VERSION ""

NS_ :

BS_:

BU_:

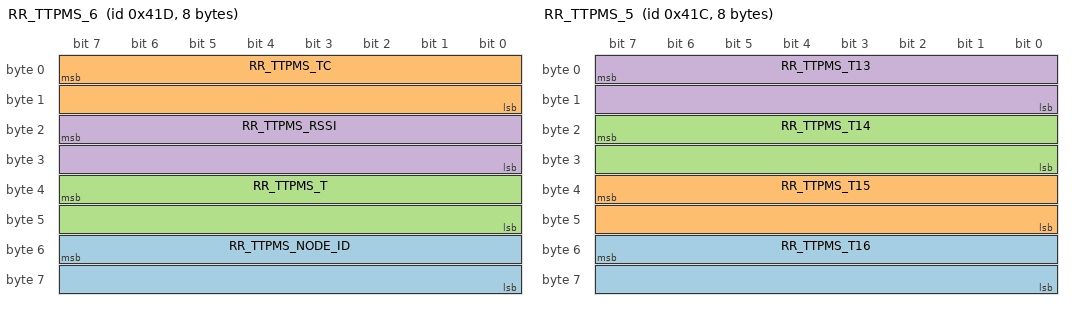
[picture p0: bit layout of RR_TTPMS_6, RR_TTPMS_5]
BO_ 1053 RR_TTPMS_6: 8 Vector__XXX
 SG_ RR_TTPMS_NODE_ID : 55|16@0+ (1,0) [0|65535] "" Vector__XXX
 SG_ RR_TTPMS_TC : 7|16@0+ (1,0) [0|65535] "" Vector__XXX
 SG_ RR_TTPMS_T : 39|16@0+ (0.1,-100) [-100|6453.5] "�C" Vector__XXX
 SG_ RR_TTPMS_RSSI : 23|16@0- (1,0) [-32768|32767] "dBm" Vector__XXX

BO_ 1052 RR_TTPMS_5: 8 Vector__XXX
 SG_ RR_TTPMS_T16 : 55|16@0+ (0.1,-100) [-100|6453.5] "�C" Vector__XXX
 SG_ RR_TTPMS_T15 : 39|16@0+ (0.1,-100) [-100|6453.5] "�C" Vector__XXX
 SG_ RR_TTPMS_T14 : 23|16@0+ (0.1,-100) [-100|6453.5] "�C" Vector__XXX
 SG_ RR_TTPMS_T13 : 7|16@0+ (0.1,-100) [-100|6453.5] "�C" Vector__XXX

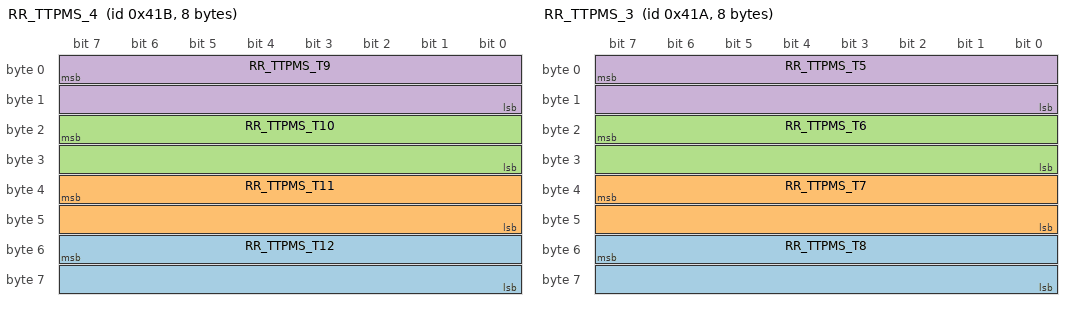
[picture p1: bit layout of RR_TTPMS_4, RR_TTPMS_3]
BO_ 1051 RR_TTPMS_4: 8 Vector__XXX
 SG_ RR_TTPMS_T12 : 55|16@0+ (0.1,-100) [-100|6453.5] "�C" Vector__XXX
 SG_ RR_TTPMS_T11 : 39|16@0+ (0.1,-100) [-100|6453.5] "�C" Vector__XXX
 SG_ RR_TTPMS_T10 : 23|16@0+ (0.1,-100) [-100|6453.5] "�C" Vector__XXX
 SG_ RR_TTPMS_T9 : 7|16@0+ (0.1,-100) [-100|6453.5] "�C" Vector__XXX

BO_ 1050 RR_TTPMS_3: 8 Vector__XXX
 SG_ RR_TTPMS_T8 : 55|16@0+ (0.1,-100) [-100|6453.5] "�C" Vector__XXX
 SG_ RR_TTPMS_T7 : 39|16@0+ (0.1,-100) [-100|6453.5] "�C" Vector__XXX
 SG_ RR_TTPMS_T6 : 23|16@0+ (0.1,-100) [-100|6453.5] "�C" Vector__XXX
 SG_ RR_TTPMS_T5 : 7|16@0+ (0.1,-100) [-100|6453.5] "�C" Vector__XXX

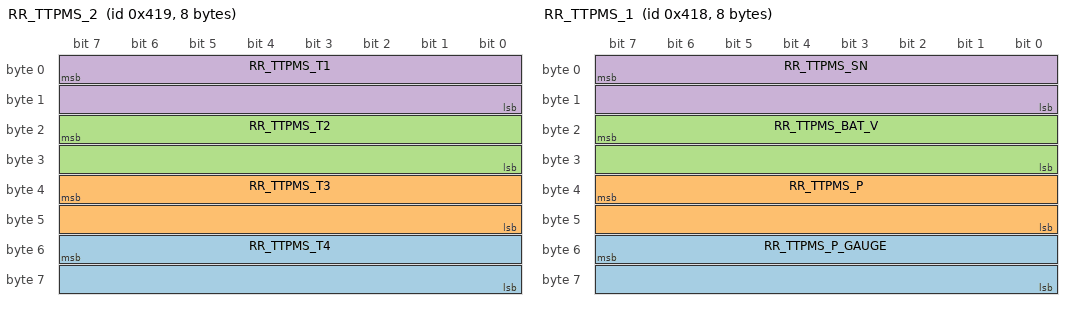
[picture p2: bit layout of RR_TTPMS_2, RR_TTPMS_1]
BO_ 1049 RR_TTPMS_2: 8 Vector__XXX
 SG_ RR_TTPMS_T4 : 55|16@0+ (0.1,-100) [-100|6453.5] "�C" Vector__XXX
 SG_ RR_TTPMS_T3 : 39|16@0+ (0.1,-100) [-100|6453.5] "�C" Vector__XXX
 SG_ RR_TTPMS_T2 : 23|16@0+ (0.1,-100) [-100|6453.5] "�C" Vector__XXX
 SG_ RR_TTPMS_T1 : 7|16@0+ (0.1,-100) [-100|6453.5] "�C" Vector__XXX

BO_ 1048 RR_TTPMS_1: 8 Vector__XXX
 SG_ RR_TTPMS_P_GAUGE : 55|16@0+ (1,0) [0|65535] "mbar" Vector__XXX
 SG_ RR_TTPMS_P : 39|16@0+ (1,0) [0|65535] "mbar" Vector__XXX
 SG_ RR_TTPMS_BAT_V : 23|16@0+ (1,0) [0|65535] "mV" Vector__XXX
 SG_ RR_TTPMS_SN : 7|16@0+ (1,0) [0|65535] "" Vector__XXX

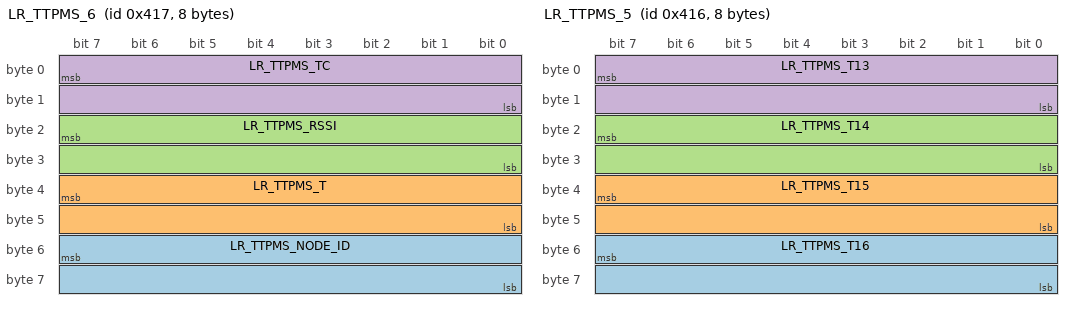
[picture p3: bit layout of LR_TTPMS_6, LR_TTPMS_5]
BO_ 1047 LR_TTPMS_6: 8 Vector__XXX
 SG_ LR_TTPMS_NODE_ID : 55|16@0+ (1,0) [0|65535] "" Vector__XXX
 SG_ LR_TTPMS_T : 39|16@0+ (0.1,-100) [-100|6453.5] "�C" Vector__XXX
 SG_ LR_TTPMS_RSSI : 23|16@0- (1,0) [-32768|32767] "dBm" Vector__XXX
 SG_ LR_TTPMS_TC : 7|16@0+ (1,0) [0|65535] "" Vector__XXX

BO_ 1046 LR_TTPMS_5: 8 Vector__XXX
 SG_ LR_TTPMS_T16 : 55|16@0+ (0.1,-100) [-100|6453.5] "�C" Vector__XXX
 SG_ LR_TTPMS_T15 : 39|16@0+ (0.1,-100) [-100|6453.5] "�C" Vector__XXX
 SG_ LR_TTPMS_T14 : 23|16@0+ (0.1,-100) [-100|6453.5] "�C" Vector__XXX
 SG_ LR_TTPMS_T13 : 7|16@0+ (0.1,-100) [-100|6453.5] "�C" Vector__XXX

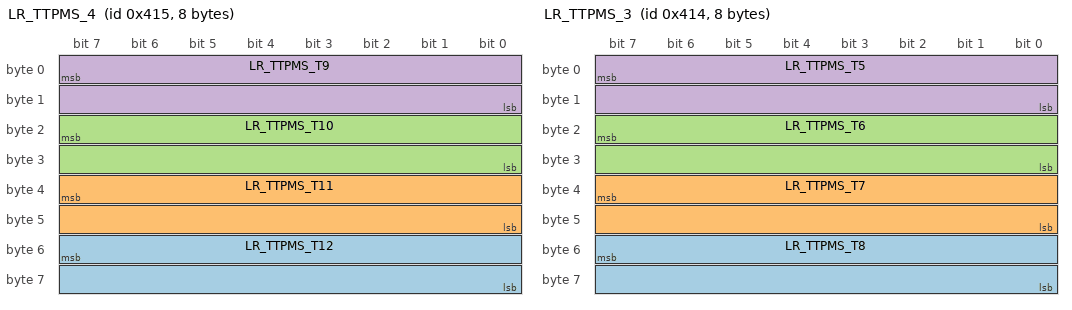
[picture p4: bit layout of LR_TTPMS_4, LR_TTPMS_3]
BO_ 1045 LR_TTPMS_4: 8 Vector__XXX
 SG_ LR_TTPMS_T12 : 55|16@0+ (0.1,-100) [-100|6453.5] "�C" Vector__XXX
 SG_ LR_TTPMS_T11 : 39|16@0+ (0.1,-100) [-100|6453.5] "�C" Vector__XXX
 SG_ LR_TTPMS_T10 : 23|16@0+ (0.1,-100) [-100|6453.5] "�C" Vector__XXX
 SG_ LR_TTPMS_T9 : 7|16@0+ (0.1,-100) [-100|6453.5] "�C" Vector__XXX

BO_ 1044 LR_TTPMS_3: 8 Vector__XXX
 SG_ LR_TTPMS_T8 : 55|16@0+ (0.1,-100) [-100|6453.5] "�C" Vector__XXX
 SG_ LR_TTPMS_T7 : 39|16@0+ (0.1,-100) [-100|6453.5] "�C" Vector__XXX
 SG_ LR_TTPMS_T6 : 23|16@0+ (0.1,-100) [-100|6453.5] "�C" Vector__XXX
 SG_ LR_TTPMS_T5 : 7|16@0+ (0.1,-100) [-100|6453.5] "�C" Vector__XXX

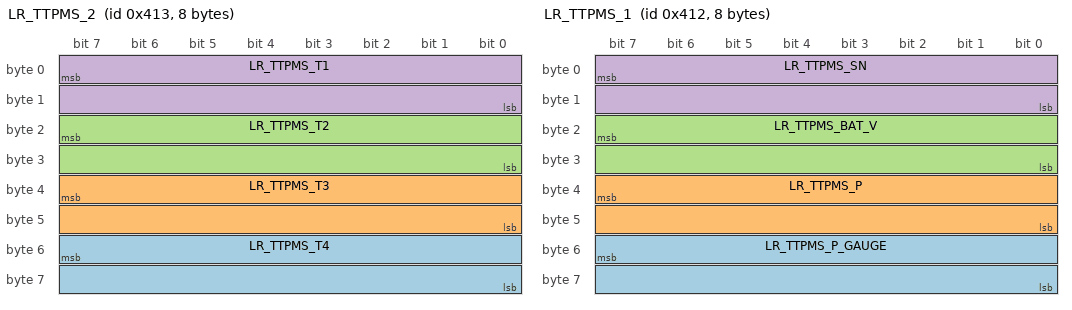
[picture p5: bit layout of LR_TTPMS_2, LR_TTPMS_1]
BO_ 1043 LR_TTPMS_2: 8 Vector__XXX
 SG_ LR_TTPMS_T4 : 55|16@0+ (0.1,-100) [-100|6453.5] "�C" Vector__XXX
 SG_ LR_TTPMS_T3 : 39|16@0+ (0.1,-100) [-100|6453.5] "�C" Vector__XXX
 SG_ LR_TTPMS_T2 : 23|16@0+ (0.1,-100) [-100|6453.5] "�C" Vector__XXX
 SG_ LR_TTPMS_T1 : 7|16@0+ (0.1,-100) [-100|6453.5] "�C" Vector__XXX

BO_ 1042 LR_TTPMS_1: 8 Vector__XXX
 SG_ LR_TTPMS_P_GAUGE : 55|16@0+ (1,0) [0|65535] "mbar" Vector__XXX
 SG_ LR_TTPMS_P : 39|16@0+ (1,0) [0|65535] "mbar" Vector__XXX
 SG_ LR_TTPMS_BAT_V : 23|16@0+ (1,0) [0|65535] "mV" Vector__XXX
 SG_ LR_TTPMS_SN : 7|16@0+ (1,0) [0|65535] "" Vector__XXX

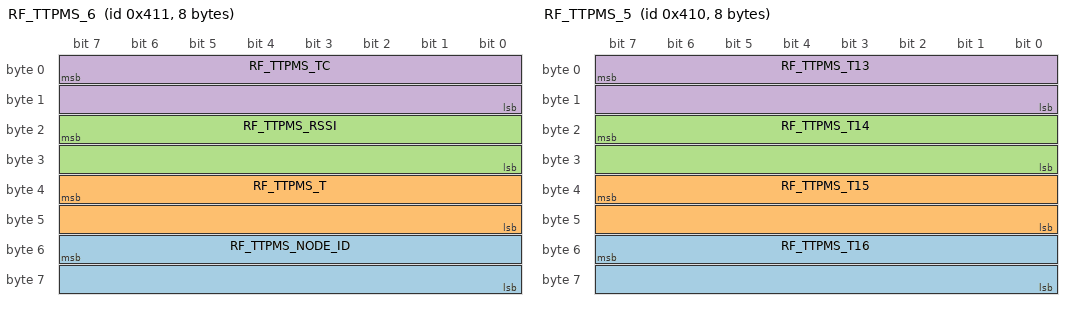
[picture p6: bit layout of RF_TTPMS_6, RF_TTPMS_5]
BO_ 1041 RF_TTPMS_6: 8 Vector__XXX
 SG_ RF_TTPMS_NODE_ID : 55|16@0+ (1,0) [0|65535] "" Vector__XXX
 SG_ RF_TTPMS_T : 39|16@0+ (0.1,-100) [-100|6453.5] "�C" Vector__XXX
 SG_ RF_TTPMS_RSSI : 23|16@0- (1,0) [-32768|32767] "dBm" Vector__XXX
 SG_ RF_TTPMS_TC : 7|16@0+ (1,0) [0|65535] "" Vector__XXX

BO_ 1040 RF_TTPMS_5: 8 Vector__XXX
 SG_ RF_TTPMS_T16 : 55|16@0+ (0.1,-100) [-100|6453.5] "�C" Vector__XXX
 SG_ RF_TTPMS_T15 : 39|16@0+ (0.1,-100) [-100|6453.5] "�C" Vector__XXX
 SG_ RF_TTPMS_T14 : 23|16@0+ (0.1,-100) [-100|6453.5] "�C" Vector__XXX
 SG_ RF_TTPMS_T13 : 7|16@0+ (0.1,-100) [-100|6453.5] "�C" Vector__XXX

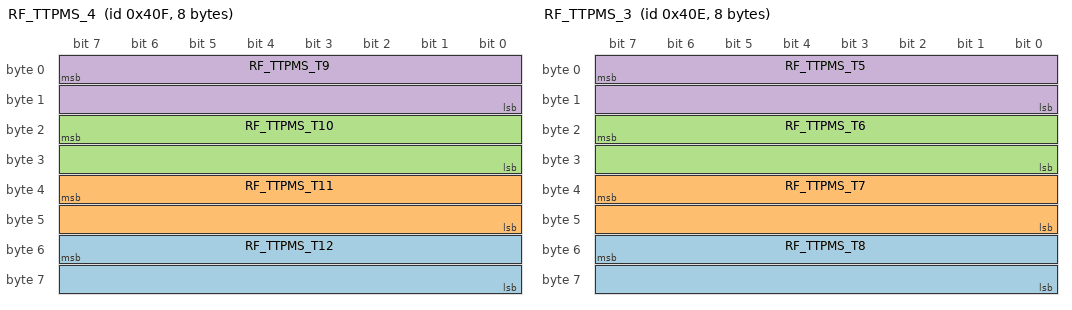
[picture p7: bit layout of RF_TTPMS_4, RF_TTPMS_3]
BO_ 1039 RF_TTPMS_4: 8 Vector__XXX
 SG_ RF_TTPMS_T12 : 55|16@0+ (0.1,-100) [-100|6453.5] "�C" Vector__XXX
 SG_ RF_TTPMS_T11 : 39|16@0+ (0.1,-100) [-100|6453.5] "�C" Vector__XXX
 SG_ RF_TTPMS_T10 : 23|16@0+ (0.1,-100) [-100|6453.5] "�C" Vector__XXX
 SG_ RF_TTPMS_T9 : 7|16@0+ (0.1,-100) [-100|6453.5] "�C" Vector__XXX

BO_ 1038 RF_TTPMS_3: 8 Vector__XXX
 SG_ RF_TTPMS_T8 : 55|16@0+ (0.1,-100) [-100|6453.5] "�C" Vector__XXX
 SG_ RF_TTPMS_T7 : 39|16@0+ (0.1,-100) [-100|6453.5] "�C" Vector__XXX
 SG_ RF_TTPMS_T6 : 23|16@0+ (0.1,-100) [-100|6453.5] "�C" Vector__XXX
 SG_ RF_TTPMS_T5 : 7|16@0+ (0.1,-100) [-100|6453.5] "�C" Vector__XXX

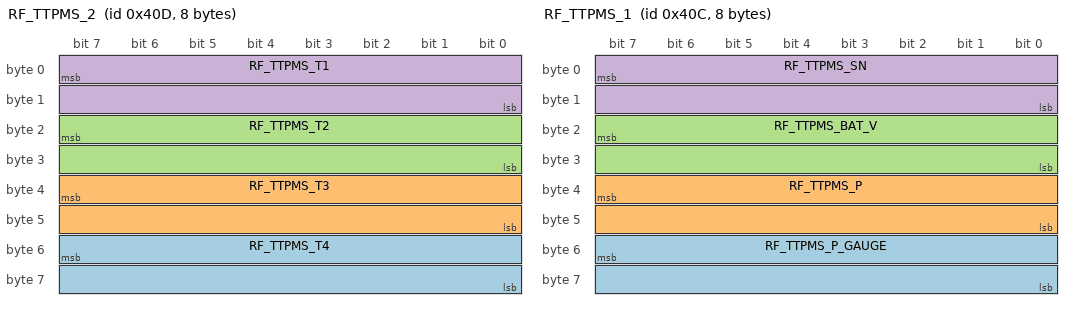
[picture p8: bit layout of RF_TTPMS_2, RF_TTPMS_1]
BO_ 1037 RF_TTPMS_2: 8 Vector__XXX
 SG_ RF_TTPMS_T4 : 55|16@0+ (0.1,-100) [-100|6453.5] "�C" Vector__XXX
 SG_ RF_TTPMS_T3 : 39|16@0+ (0.1,-100) [-100|6453.5] "�C" Vector__XXX
 SG_ RF_TTPMS_T2 : 23|16@0+ (0.1,-100) [-100|6453.5] "�C" Vector__XXX
 SG_ RF_TTPMS_T1 : 7|16@0+ (0.1,-100) [-100|6453.5] "�C" Vector__XXX

BO_ 1036 RF_TTPMS_1: 8 Vector__XXX
 SG_ RF_TTPMS_P_GAUGE : 55|16@0+ (1,0) [0|65535] "mbar" Vector__XXX
 SG_ RF_TTPMS_P : 39|16@0+ (1,0) [0|65535] "mbar" Vector__XXX
 SG_ RF_TTPMS_BAT_V : 23|16@0+ (1,0) [0|65535] "mV" Vector__XXX
 SG_ RF_TTPMS_SN : 7|16@0+ (1,0) [0|65535] "" Vector__XXX

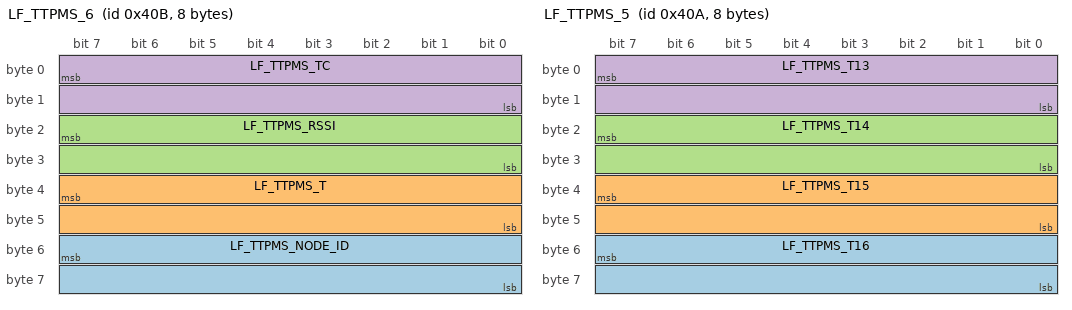
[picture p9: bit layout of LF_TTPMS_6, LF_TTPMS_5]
BO_ 1035 LF_TTPMS_6: 8 Vector__XXX
 SG_ LF_TTPMS_NODE_ID : 55|16@0+ (1,0) [0|65535] "" Vector__XXX
 SG_ LF_TTPMS_T : 39|16@0+ (0.1,-100) [-100|6453.5] "�C" Vector__XXX
 SG_ LF_TTPMS_RSSI : 23|16@0- (1,0) [-32768|32767] "dBm" Vector__XXX
 SG_ LF_TTPMS_TC : 7|16@0+ (1,0) [0|65535] "" Vector__XXX

BO_ 1034 LF_TTPMS_5: 8 Vector__XXX
 SG_ LF_TTPMS_T16 : 55|16@0+ (0.1,-100) [-100|6453.5] "�C" Vector__XXX
 SG_ LF_TTPMS_T15 : 39|16@0+ (0.1,-100) [-100|6453.5] "�C" Vector__XXX
 SG_ LF_TTPMS_T14 : 23|16@0+ (0.1,-100) [-100|6453.5] "�C" Vector__XXX
 SG_ LF_TTPMS_T13 : 7|16@0+ (0.1,-100) [-100|6453.5] "�C" Vector__XXX

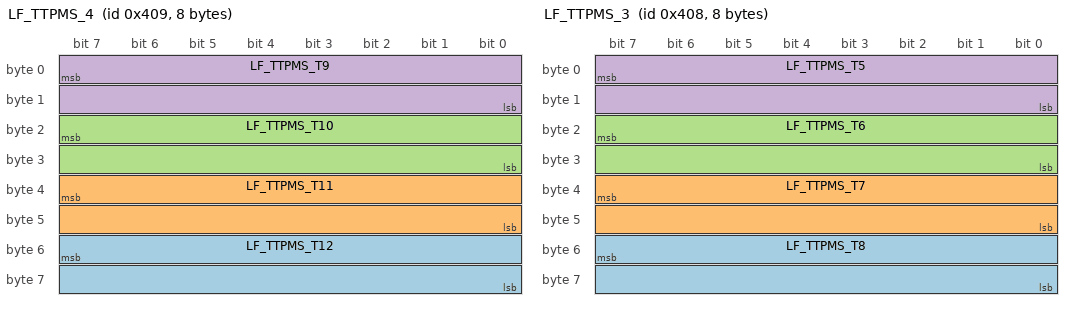
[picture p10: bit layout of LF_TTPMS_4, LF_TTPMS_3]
BO_ 1033 LF_TTPMS_4: 8 Vector__XXX
 SG_ LF_TTPMS_T12 : 55|16@0+ (0.1,-100) [-100|6453.5] "�C" Vector__XXX
 SG_ LF_TTPMS_T11 : 39|16@0+ (0.1,-100) [-100|6453.5] "�C" Vector__XXX
 SG_ LF_TTPMS_T10 : 23|16@0+ (0.1,-100) [-100|6453.5] "�C" Vector__XXX
 SG_ LF_TTPMS_T9 : 7|16@0+ (0.1,-100) [-100|6453.5] "�C" Vector__XXX

BO_ 1032 LF_TTPMS_3: 8 Vector__XXX
 SG_ LF_TTPMS_T8 : 55|16@0+ (0.1,-100) [-100|6453.5] "�C" Vector__XXX
 SG_ LF_TTPMS_T7 : 39|16@0+ (0.1,-100) [-100|6453.5] "�C" Vector__XXX
 SG_ LF_TTPMS_T6 : 23|16@0+ (0.1,-100) [-100|6453.5] "�C" Vector__XXX
 SG_ LF_TTPMS_T5 : 7|16@0+ (0.1,-100) [-100|6453.5] "�C" Vector__XXX

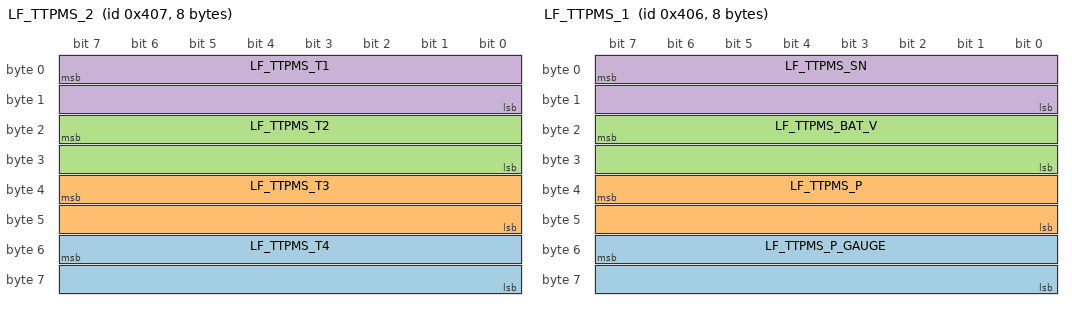
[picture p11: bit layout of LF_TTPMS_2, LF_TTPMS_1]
BO_ 1031 LF_TTPMS_2: 8 Vector__XXX
 SG_ LF_TTPMS_T4 : 55|16@0+ (0.1,-100) [-100|6453.5] "�C" Vector__XXX
 SG_ LF_TTPMS_T3 : 39|16@0+ (0.1,-100) [-100|6453.5] "�C" Vector__XXX
 SG_ LF_TTPMS_T2 : 23|16@0+ (0.1,-100) [-100|6453.5] "�C" Vector__XXX
 SG_ LF_TTPMS_T1 : 7|16@0+ (0.1,-100) [-100|6453.5] "�C" Vector__XXX

BO_ 1030 LF_TTPMS_1: 8 Vector__XXX
 SG_ LF_TTPMS_P_GAUGE : 55|16@0+ (1,0) [0|65535] "mbar" Vector__XXX
 SG_ LF_TTPMS_P : 39|16@0+ (1,0) [0|65535] "mbar" Vector__XXX
 SG_ LF_TTPMS_BAT_V : 23|16@0+ (1,0) [0|65535] "mV" Vector__XXX
 SG_ LF_TTPMS_SN : 7|16@0+ (1,0) [0|65535] "" Vector__XXX

BA_DEF_ BO_  "GenMsgCycleTime" INT 0 0;
BA_DEF_DEF_  "GenMsgCycleTime" 0;
BA_ "GenMsgCycleTime" BO_ 1053 1250;
BA_ "GenMsgCycleTime" BO_ 1052 1250;
BA_ "GenMsgCycleTime" BO_ 1051 1250;
BA_ "GenMsgCycleTime" BO_ 1050 1250;
BA_ "GenMsgCycleTime" BO_ 1049 1250;
BA_ "GenMsgCycleTime" BO_ 1048 1250;
BA_ "GenMsgCycleTime" BO_ 1047 1250;
BA_ "GenMsgCycleTime" BO_ 1046 1250;
BA_ "GenMsgCycleTime" BO_ 1045 1250;
BA_ "GenMsgCycleTime" BO_ 1044 1250;
BA_ "GenMsgCycleTime" BO_ 1043 1250;
BA_ "GenMsgCycleTime" BO_ 1042 1250;
BA_ "GenMsgCycleTime" BO_ 1041 1250;
BA_ "GenMsgCycleTime" BO_ 1040 1250;
BA_ "GenMsgCycleTime" BO_ 1039 1250;
BA_ "GenMsgCycleTime" BO_ 1038 1250;
BA_ "GenMsgCycleTime" BO_ 1037 1250;
BA_ "GenMsgCycleTime" BO_ 1036 1250;
BA_ "GenMsgCycleTime" BO_ 1035 1250;
BA_ "GenMsgCycleTime" BO_ 1034 1250;
BA_ "GenMsgCycleTime" BO_ 1033 1250;
BA_ "GenMsgCycleTime" BO_ 1032 1250;
BA_ "GenMsgCycleTime" BO_ 1031 1250;
BA_ "GenMsgCycleTime" BO_ 1030 1250;
